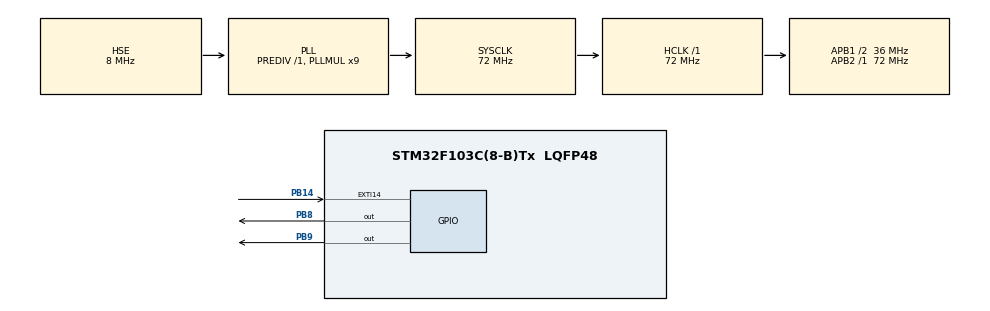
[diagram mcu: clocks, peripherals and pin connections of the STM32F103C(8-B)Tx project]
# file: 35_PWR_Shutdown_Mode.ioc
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Mcu.Family=STM32F1
Mcu.Name=STM32F103C(8-B)Tx
Mcu.Package=LQFP48
NVIC.EXTI15_10_IRQn=true\:0\:0\:false\:false\:true\:true\:true\:true
NVIC.PriorityGroup=NVIC_PRIORITYGROUP_4
PA13.Mode=Serial_Wire
PA13.Signal=SYS_JTMS-SWDIO
PA14.Mode=Serial_Wire
PA14.Signal=SYS_JTCK-SWCLK
PB14.Signal=GPXTI14
PB8.Signal=GPIO_Output
PB9.Signal=GPIO_Output
PD0-OSC_IN.Mode=HSE-External-Oscillator
PD0-OSC_IN.Signal=RCC_OSC_IN
PD1-OSC_OUT.Mode=HSE-External-Oscillator
PD1-OSC_OUT.Signal=RCC_OSC_OUT
ProjectManager.HeapSize=0x200
ProjectManager.StackSize=0x400
ProjectManager.TargetToolchain=MDK-ARM V5.32
RCC.AHBFreq_Value=72000000
RCC.APB1CLKDivider=RCC_HCLK_DIV2
RCC.APB1Freq_Value=36000000
RCC.APB1TimFreq_Value=72000000
RCC.APB2Freq_Value=72000000
RCC.APB2TimFreq_Value=72000000
RCC.HCLKFreq_Value=72000000
RCC.PLLMUL=RCC_PLL_MUL9
RCC.PLLSourceVirtual=RCC_PLLSOURCE_HSE
RCC.SYSCLKFreq_VALUE=72000000
RCC.SYSCLKSource=RCC_SYSCLKSOURCE_PLLCLK
RCC.USBFreq_Value=72000000
board=custom

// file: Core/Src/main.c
/* USER CODE BEGIN Header */
/**
 ******************************************************************************
 * @file           : main.c
 * @brief          : Main program body
 ******************************************************************************
 * @attention
 *
 * Copyright (c) 2026 STMicroelectronics.
 * All rights reserved.
 *
 * This software is licensed under terms that can be found in the LICENSE file
 * in the root directory of this software component.
 * If no LICENSE file comes with this software, it is provided AS-IS.
 *
 ******************************************************************************
 */
/* USER CODE END Header */
#include "main.h"
#include "gpio.h"

/* USER CODE BEGIN Includes */
#include "OLED.h"
#include "stm32f1xx_it.h"
/* USER CODE END Includes */

void SystemClock_Config(void);

int main(void)
{

  /* MCU Configuration--------------------------------------------------------*/

  /* Reset of all peripherals, Initializes the Flash interface and the Systick. */
  HAL_Init();

  /* Configure the system clock */
  SystemClock_Config();

  /* Initialize all configured peripherals */
  MX_GPIO_Init();
  /* USER CODE BEGIN 2 */
  OLED_Init();                     // OLED初始化
  OLED_Clear();                    // OLED清屏
  OLED_ShowString(1, 1, "Count:"); // 在第一行第一列显示字符串"Count"
  OLED_ShowString(2, 1, "clk:");   // 在第二行第一列显示字符串"clk"

  /* USER CODE END 2 */

  /* Infinite loop */
  /* USER CODE BEGIN WHILE */
  while (1)
  {
    OLED_ShowNum(1, 7, Get_Counter(), 5);              // 在第一行第七列显示计数值，长度为5位
    OLED_ShowNum(2, 5, HAL_RCC_GetSysClockFreq(), 10); // 在第二行第五列显示系统时钟频率，长度为10位
    OLED_ShowString(3, 1, "Running");
    HAL_Delay(500);                    // 延时500毫秒
    OLED_ShowString(3, 1, "        "); // 清除第三行显示的字符串
    HAL_Delay(500);                    // 延时500毫秒

    // 进入STOP模式，等待中断唤醒
    // PWR_MAINREGULATOR_ON:主调压器开启。唤醒速度快，但功耗略高
    // PWR_STOPENTRY_WFI:通过中断（Wait For Interrupt）唤醒。
    HAL_PWR_EnterSTOPMode(PWR_MAINREGULATOR_ON, PWR_STOPENTRY_WFI);

    SystemClock_Config(); // 重新配置系统时钟，因为从STOP模式唤醒后时钟设置会丢失
    /* USER CODE END WHILE */

  }
}

void SystemClock_Config(void)
{
  RCC_OscInitTypeDef RCC_OscInitStruct = {0};
  RCC_ClkInitTypeDef RCC_ClkInitStruct = {0};

  /** Initializes the RCC Oscillators according to the specified parameters
   * in the RCC_OscInitTypeDef structure.
   */
  RCC_OscInitStruct.OscillatorType = RCC_OSCILLATORTYPE_HSE;
  RCC_OscInitStruct.HSEState = RCC_HSE_ON;
  RCC_OscInitStruct.HSEPredivValue = RCC_HSE_PREDIV_DIV1;
  RCC_OscInitStruct.HSIState = RCC_HSI_ON;
  RCC_OscInitStruct.PLL.PLLState = RCC_PLL_ON;
  RCC_OscInitStruct.PLL.PLLSource = RCC_PLLSOURCE_HSE;
  RCC_OscInitStruct.PLL.PLLMUL = RCC_PLL_MUL9;
  if (HAL_RCC_OscConfig(&RCC_OscInitStruct) != HAL_OK)
  {
    Error_Handler();
  }

  /** Initializes the CPU, AHB and APB buses clocks
   */
  RCC_ClkInitStruct.ClockType = RCC_CLOCKTYPE_HCLK | RCC_CLOCKTYPE_SYSCLK | RCC_CLOCKTYPE_PCLK1 | RCC_CLOCKTYPE_PCLK2;
  RCC_ClkInitStruct.SYSCLKSource = RCC_SYSCLKSOURCE_PLLCLK;
  RCC_ClkInitStruct.AHBCLKDivider = RCC_SYSCLK_DIV1;
  RCC_ClkInitStruct.APB1CLKDivider = RCC_HCLK_DIV2;
  RCC_ClkInitStruct.APB2CLKDivider = RCC_HCLK_DIV1;

  if (HAL_RCC_ClockConfig(&RCC_ClkInitStruct, FLASH_LATENCY_2) != HAL_OK)
  {
    Error_Handler();
  }
}

void Error_Handler(void)
{
  __disable_irq();
  while (1)
  {
  }
}
